# cbass_CBASS_FW_45000000h register map
Vendor: Texas Instruments
Registers are 32-bit, read-write, reset 0x0 unless marked. A register's access mark holds for its fields unless they carry their own. Offsets are as the file gives them; [hi:lo] are bit positions; {n}, {i} and the like mark numbered series; 'fields as' and 'values as' point back to an identical list.

## cbass_fw (part 2 of 2)
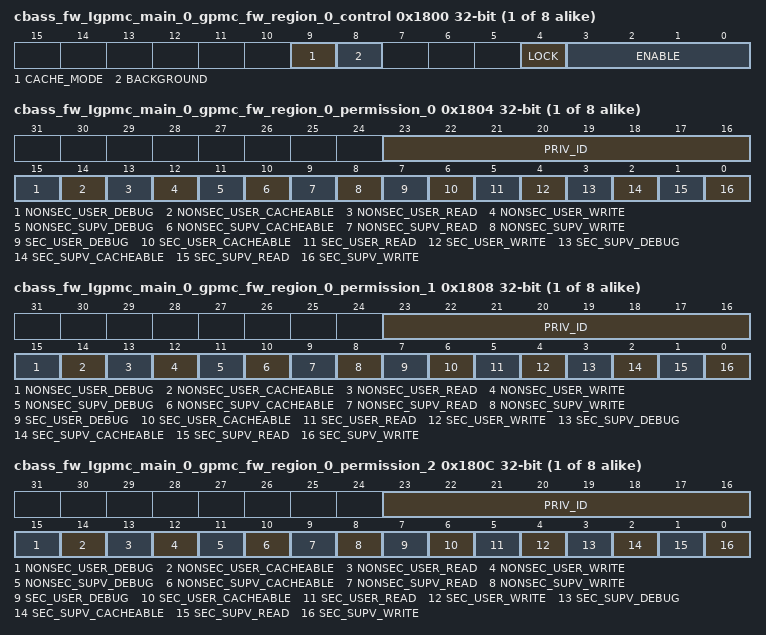
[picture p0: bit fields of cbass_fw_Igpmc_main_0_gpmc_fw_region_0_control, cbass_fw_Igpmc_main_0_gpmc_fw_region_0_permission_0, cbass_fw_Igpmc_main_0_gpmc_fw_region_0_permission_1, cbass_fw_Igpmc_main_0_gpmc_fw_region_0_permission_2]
{0x1800+0x20*i} cbass_fw_Igpmc_main_0_gpmc_fw_region_{i}_control access not given (i=0..7) — The FW Region {i} Control Register defines the control fields for the slave Igpmc_main_0.gpmc region {i} firewall.
  [9] CACHE_MODE rw — Cache mode for region. Set to 1 to check cache permissions. Set to 0 to ignore cache permissions. Reset Source: domain_default_rst_mod_g_rst_n
  [8] BACKGROUND rw — Background enable for region. There can be 1 backgroun region per FW and foreground regions can have overlapping addresses only with the background region. Reset Source: domain_default_rst_mod_g_rst_n
  [4] LOCK — Lock region. Once set region values cannot be modified. Reset Source: domain_default_rst_mod_g_rst_n (access R/W1TS)
  [3:0] ENABLE rw — Enable region. A value of 0xA enables, others disable. Reset Source: domain_default_rst_mod_g_rst_n
{0x1804+0x20*i} cbass_fw_Igpmc_main_0_gpmc_fw_region_{i}_permission_0 (i=0..7) — The FW Region {i} Permission 0 Register defines the permissions for the slave Igpmc_main_0.gpmc region {i} firewall.
  [23:16] PRIV_ID — Allowed privid. Reset Source: domain_default_rst_mod_g_rst_n
  [15] NONSEC_USER_DEBUG — Non-secure user debug allowed. Reset Source: domain_default_rst_mod_g_rst_n
  [14] NONSEC_USER_CACHEABLE — Non-secure user cacheable allowed. Reset Source: domain_default_rst_mod_g_rst_n
  [13] NONSEC_USER_READ — Non-secure user read allowed. Reset Source: domain_default_rst_mod_g_rst_n
  [12] NONSEC_USER_WRITE — Non-secure user write allowed. Reset Source: domain_default_rst_mod_g_rst_n
  [11] NONSEC_SUPV_DEBUG — Non-secure supervisor debug allowed. Reset Source: domain_default_rst_mod_g_rst_n
  [10] NONSEC_SUPV_CACHEABLE — Non-secure supervisor cacheable allowed. Reset Source: domain_default_rst_mod_g_rst_n
  [9] NONSEC_SUPV_READ — Non-secure supervisor read allowed. Reset Source: domain_default_rst_mod_g_rst_n
  [8] NONSEC_SUPV_WRITE — Non-secure supervisor write allowed. Reset Source: domain_default_rst_mod_g_rst_n
  [7] SEC_USER_DEBUG — Secure user debug allowed. Reset Source: domain_default_rst_mod_g_rst_n
  [6] SEC_USER_CACHEABLE — Secure user cacheable allowed. Reset Source: domain_default_rst_mod_g_rst_n
  [5] SEC_USER_READ — Secure user read allowed. Reset Source: domain_default_rst_mod_g_rst_n
  [4] SEC_USER_WRITE — Secure user write allowed. Reset Source: domain_default_rst_mod_g_rst_n
  [3] SEC_SUPV_DEBUG — Secure supervisor debug allowed. Reset Source: domain_default_rst_mod_g_rst_n
  [2] SEC_SUPV_CACHEABLE — Secure supervisor cacheable allowed. Reset Source: domain_default_rst_mod_g_rst_n
  [1] SEC_SUPV_READ — Secure supervisor read allowed. Reset Source: domain_default_rst_mod_g_rst_n
  [0] SEC_SUPV_WRITE — Secure supervisor write allowed. Reset Source: domain_default_rst_mod_g_rst_n
{0x1808+0x20*i} cbass_fw_Igpmc_main_0_gpmc_fw_region_{i}_permission_1 (i=0..7) — The FW Region {i} Permission 1 Register defines the permissions for the slave Igpmc_main_0.gpmc region {i} firewall.
  fields as cbass_fw_Igpmc_main_0_gpmc_fw_region_0_permission_0
{0x180C+0x20*i} cbass_fw_Igpmc_main_0_gpmc_fw_region_{i}_permission_2 (i=0..7) — The FW Region {i} Permission 2 Register defines the permissions for the slave Igpmc_main_0.gpmc region {i} firewall.
  fields as cbass_fw_Igpmc_main_0_gpmc_fw_region_0_permission_0
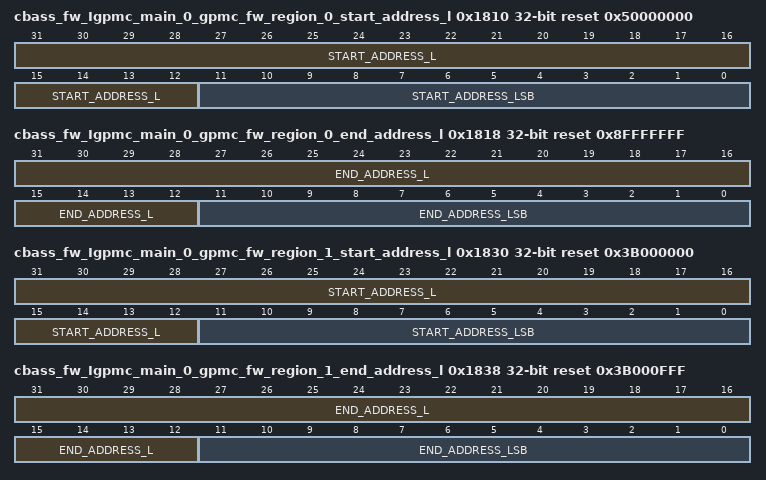
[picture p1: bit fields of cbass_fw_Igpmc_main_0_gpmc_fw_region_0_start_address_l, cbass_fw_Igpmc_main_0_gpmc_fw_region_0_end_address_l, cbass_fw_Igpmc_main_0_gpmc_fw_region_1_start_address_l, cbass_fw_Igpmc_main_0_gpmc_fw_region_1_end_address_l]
0x1810 cbass_fw_Igpmc_main_0_gpmc_fw_region_0_start_address_l access per field reset 0x50000000 — The FW Region 0 Start Address Low Register defines the start address bits 31 to 0 for the slave Igpmc_main_0.gpmc region 0 firewall.
  [31:12] START_ADDRESS_L rw — Start address bits 31 to 12. Lowest 12 bits are forced to 0 as address must be 4KB aligned. Reset Source: domain_default_rst_mod_g_rst_n
  [11:0] START_ADDRESS_LSB ro — Start address bits 11 to 0 are forced to 0 as address must be 4KB aligned. Reset Source: domain_default_rst_mod_g_rst_n
{0x1814+0x20*i} cbass_fw_Igpmc_main_0_gpmc_fw_region_{i}_start_address_h (i=0..7) — The FW Region {i} Start Address High Register defines the start address bits 47 to 32 for the slave Igpmc_main_0.gpmc region {i} firewall.
  [15:0] START_ADDRESS_H — Start address bits 47 to 32. Reset Source: domain_default_rst_mod_g_rst_n
0x1818 cbass_fw_Igpmc_main_0_gpmc_fw_region_0_end_address_l access per field reset 0x8FFFFFFF — The FW Region 0 End Address Low Register defines the end address bits 31 to 0 to include for the slave Igpmc_main_0.gpmc region 0 firewall.
  [31:12] END_ADDRESS_L rw — End address bits 31 to 12 to include in the match. Lowest 12 bits are forced to 1s as address must be 4KB aligned. Reset Source: domain_default_rst_mod_g_rst_n
  [11:0] END_ADDRESS_LSB ro — End address bits 11 to 0 are forced to 1s as address must be 4KB aligned minus 1. Reset Source: domain_default_rst_mod_g_rst_n
{0x181C+0x20*i} cbass_fw_Igpmc_main_0_gpmc_fw_region_{i}_end_address_h (i=0..7) — The FW Region {i} End Address High Register defines the end address bits 47 to 32 to include for the slave Igpmc_main_0.gpmc region {i} firewall.
  [15:0] END_ADDRESS_H — End address bits 47 to 32 to include in the match. Reset Source: domain_default_rst_mod_g_rst_n
0x1830 cbass_fw_Igpmc_main_0_gpmc_fw_region_1_start_address_l access per field reset 0x3B000000 — The FW Region 1 Start Address Low Register defines the start address bits 31 to 0 for the slave Igpmc_main_0.gpmc region 1 firewall.
  fields as cbass_fw_Igpmc_main_0_gpmc_fw_region_0_start_address_l
0x1838 cbass_fw_Igpmc_main_0_gpmc_fw_region_1_end_address_l access per field reset 0x3B000FFF — The FW Region 1 End Address Low Register defines the end address bits 31 to 0 to include for the slave Igpmc_main_0.gpmc region 1 firewall.
  fields as cbass_fw_Igpmc_main_0_gpmc_fw_region_0_end_address_l
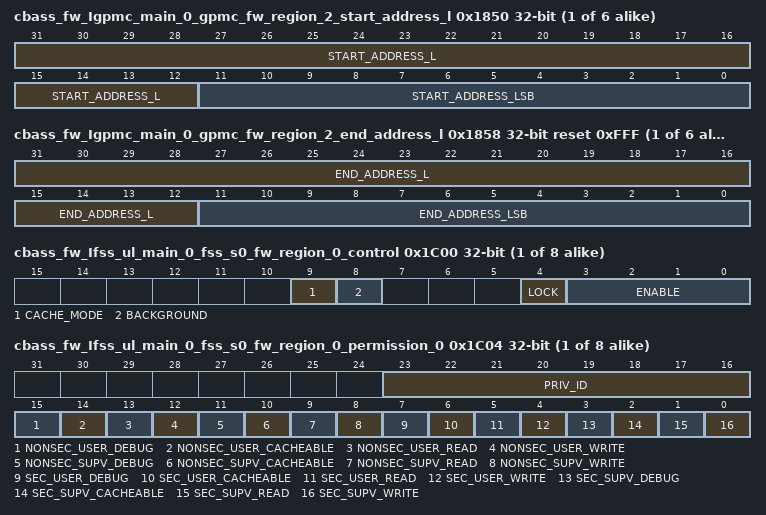
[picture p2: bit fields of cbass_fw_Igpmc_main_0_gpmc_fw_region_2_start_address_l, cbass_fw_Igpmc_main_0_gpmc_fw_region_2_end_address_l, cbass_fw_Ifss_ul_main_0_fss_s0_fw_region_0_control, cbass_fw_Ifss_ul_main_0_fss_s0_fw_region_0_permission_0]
{0x1810+0x20*i} cbass_fw_Igpmc_main_0_gpmc_fw_region_{i}_start_address_l access per field (i=2..7) — The FW Region {i} Start Address Low Register defines the start address bits 31 to 0 for the slave Igpmc_main_0.gpmc region {i} firewall.
  fields as cbass_fw_Igpmc_main_0_gpmc_fw_region_0_start_address_l
{0x1818+0x20*i} cbass_fw_Igpmc_main_0_gpmc_fw_region_{i}_end_address_l access per field reset 0xFFF (i=2..7) — The FW Region {i} End Address Low Register defines the end address bits 31 to 0 to include for the slave Igpmc_main_0.gpmc region {i} firewall.
  fields as cbass_fw_Igpmc_main_0_gpmc_fw_region_0_end_address_l
{0x1C00+0x20*i} cbass_fw_Ifss_ul_main_0_fss_s0_fw_region_{i}_control access not given (i=0..7) — The FW Region {i} Control Register defines the control fields for the slave Ifss_ul_main_0.fss_s0 region {i} firewall.
  fields as cbass_fw_Igpmc_main_0_gpmc_fw_region_0_control
{0x1C04+0x20*i} cbass_fw_Ifss_ul_main_0_fss_s0_fw_region_{i}_permission_0 (i=0..7) — The FW Region {i} Permission 0 Register defines the permissions for the slave Ifss_ul_main_0.fss_s0 region {i} firewall.
  fields as cbass_fw_Igpmc_main_0_gpmc_fw_region_0_permission_0
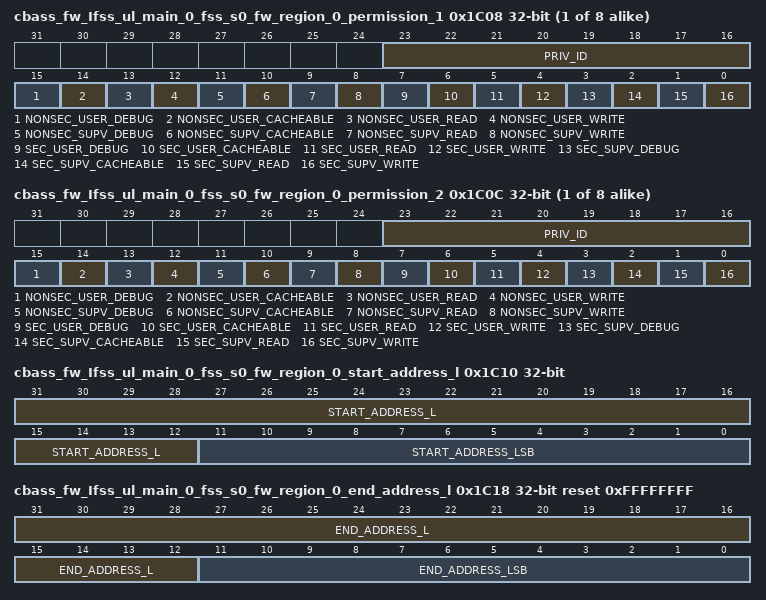
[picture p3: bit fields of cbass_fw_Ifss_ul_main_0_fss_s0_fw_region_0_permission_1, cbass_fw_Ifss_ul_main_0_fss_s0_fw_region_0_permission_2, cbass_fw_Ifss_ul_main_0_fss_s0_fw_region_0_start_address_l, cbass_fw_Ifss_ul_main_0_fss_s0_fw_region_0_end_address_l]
{0x1C08+0x20*i} cbass_fw_Ifss_ul_main_0_fss_s0_fw_region_{i}_permission_1 (i=0..7) — The FW Region {i} Permission 1 Register defines the permissions for the slave Ifss_ul_main_0.fss_s0 region {i} firewall.
  fields as cbass_fw_Igpmc_main_0_gpmc_fw_region_0_permission_0
{0x1C0C+0x20*i} cbass_fw_Ifss_ul_main_0_fss_s0_fw_region_{i}_permission_2 (i=0..7) — The FW Region {i} Permission 2 Register defines the permissions for the slave Ifss_ul_main_0.fss_s0 region {i} firewall.
  fields as cbass_fw_Igpmc_main_0_gpmc_fw_region_0_permission_0
0x1C10 cbass_fw_Ifss_ul_main_0_fss_s0_fw_region_0_start_address_l access per field — The FW Region 0 Start Address Low Register defines the start address bits 31 to 0 for the slave Ifss_ul_main_0.fss_s0 region 0 firewall.
  fields as cbass_fw_Igpmc_main_0_gpmc_fw_region_0_start_address_l
0x1C14 cbass_fw_Ifss_ul_main_0_fss_s0_fw_region_0_start_address_h reset 0x4 — The FW Region 0 Start Address High Register defines the start address bits 47 to 32 for the slave Ifss_ul_main_0.fss_s0 region 0 firewall.
  fields as cbass_fw_Igpmc_main_0_gpmc_fw_region_0_start_address_h
0x1C18 cbass_fw_Ifss_ul_main_0_fss_s0_fw_region_0_end_address_l access per field reset 0xFFFFFFFF — The FW Region 0 End Address Low Register defines the end address bits 31 to 0 to include for the slave Ifss_ul_main_0.fss_s0 region 0 firewall.
  fields as cbass_fw_Igpmc_main_0_gpmc_fw_region_0_end_address_l
0x1C1C cbass_fw_Ifss_ul_main_0_fss_s0_fw_region_0_end_address_h reset 0x4 — The FW Region 0 End Address High Register defines the end address bits 47 to 32 to include for the slave Ifss_ul_main_0.fss_s0 region 0 firewall.
  fields as cbass_fw_Igpmc_main_0_gpmc_fw_region_0_end_address_h
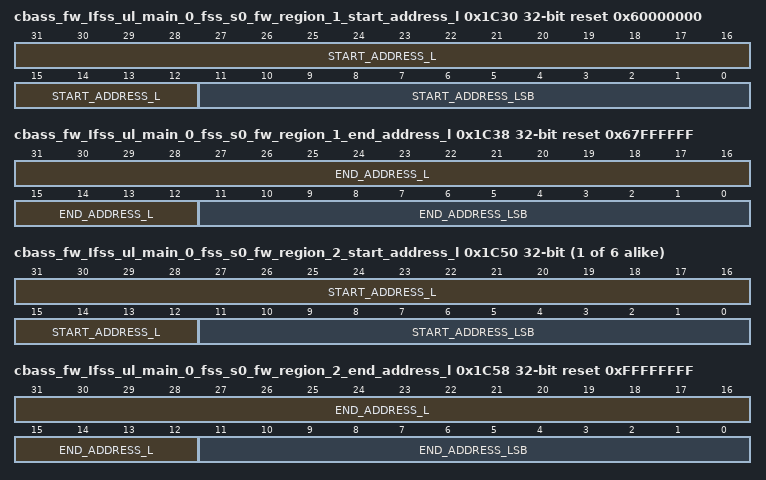
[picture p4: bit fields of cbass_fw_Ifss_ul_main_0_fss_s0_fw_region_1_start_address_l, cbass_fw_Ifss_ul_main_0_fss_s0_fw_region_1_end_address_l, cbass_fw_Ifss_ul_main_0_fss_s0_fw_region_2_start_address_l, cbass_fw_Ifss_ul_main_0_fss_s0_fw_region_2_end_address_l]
0x1C30 cbass_fw_Ifss_ul_main_0_fss_s0_fw_region_1_start_address_l access per field reset 0x60000000 — The FW Region 1 Start Address Low Register defines the start address bits 31 to 0 for the slave Ifss_ul_main_0.fss_s0 region 1 firewall.
  fields as cbass_fw_Igpmc_main_0_gpmc_fw_region_0_start_address_l
0x1C34 cbass_fw_Ifss_ul_main_0_fss_s0_fw_region_1_start_address_h — The FW Region 1 Start Address High Register defines the start address bits 47 to 32 for the slave Ifss_ul_main_0.fss_s0 region 1 firewall.
  fields as cbass_fw_Igpmc_main_0_gpmc_fw_region_0_start_address_h
0x1C38 cbass_fw_Ifss_ul_main_0_fss_s0_fw_region_1_end_address_l access per field reset 0x67FFFFFF — The FW Region 1 End Address Low Register defines the end address bits 31 to 0 to include for the slave Ifss_ul_main_0.fss_s0 region 1 firewall.
  fields as cbass_fw_Igpmc_main_0_gpmc_fw_region_0_end_address_l
0x1C3C cbass_fw_Ifss_ul_main_0_fss_s0_fw_region_1_end_address_h — The FW Region 1 End Address High Register defines the end address bits 47 to 32 to include for the slave Ifss_ul_main_0.fss_s0 region 1 firewall.
  fields as cbass_fw_Igpmc_main_0_gpmc_fw_region_0_end_address_h
{0x1C10+0x20*i} cbass_fw_Ifss_ul_main_0_fss_s0_fw_region_{i}_start_address_l access per field (i=2..7) — The FW Region {i} Start Address Low Register defines the start address bits 31 to 0 for the slave Ifss_ul_main_0.fss_s0 region {i} firewall.
  fields as cbass_fw_Igpmc_main_0_gpmc_fw_region_0_start_address_l
0x1C54 cbass_fw_Ifss_ul_main_0_fss_s0_fw_region_2_start_address_h reset 0x5 — The FW Region 2 Start Address High Register defines the start address bits 47 to 32 for the slave Ifss_ul_main_0.fss_s0 region 2 firewall.
  fields as cbass_fw_Igpmc_main_0_gpmc_fw_region_0_start_address_h
0x1C58 cbass_fw_Ifss_ul_main_0_fss_s0_fw_region_2_end_address_l access per field reset 0xFFFFFFFF — The FW Region 2 End Address Low Register defines the end address bits 31 to 0 to include for the slave Ifss_ul_main_0.fss_s0 region 2 firewall.
  fields as cbass_fw_Igpmc_main_0_gpmc_fw_region_0_end_address_l
0x1C5C cbass_fw_Ifss_ul_main_0_fss_s0_fw_region_2_end_address_h reset 0x5 — The FW Region 2 End Address High Register defines the end address bits 47 to 32 to include for the slave Ifss_ul_main_0.fss_s0 region 2 firewall.
  fields as cbass_fw_Igpmc_main_0_gpmc_fw_region_0_end_address_h
{0x1C14+0x20*i} cbass_fw_Ifss_ul_main_0_fss_s0_fw_region_{i}_start_address_h (i=3..7) — The FW Region {i} Start Address High Register defines the start address bits 47 to 32 for the slave Ifss_ul_main_0.fss_s0 region {i} firewall.
  fields as cbass_fw_Igpmc_main_0_gpmc_fw_region_0_start_address_h
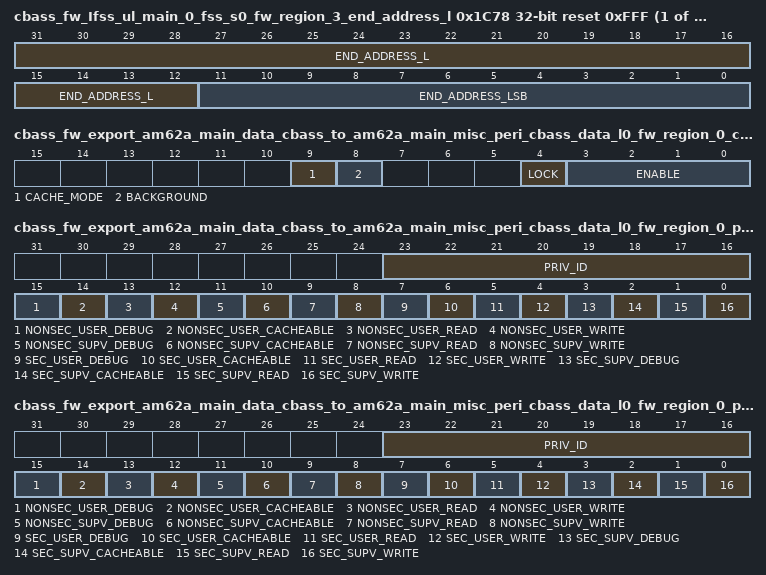
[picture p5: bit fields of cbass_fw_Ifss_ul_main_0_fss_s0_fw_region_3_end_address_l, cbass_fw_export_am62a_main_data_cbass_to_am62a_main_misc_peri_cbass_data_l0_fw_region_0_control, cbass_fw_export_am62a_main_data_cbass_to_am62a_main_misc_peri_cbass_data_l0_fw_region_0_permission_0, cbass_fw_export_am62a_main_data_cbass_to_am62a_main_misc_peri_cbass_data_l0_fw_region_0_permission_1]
{0x1C18+0x20*i} cbass_fw_Ifss_ul_main_0_fss_s0_fw_region_{i}_end_address_l access per field reset 0xFFF (i=3..7) — The FW Region {i} End Address Low Register defines the end address bits 31 to 0 to include for the slave Ifss_ul_main_0.fss_s0 region {i} firewall.
  fields as cbass_fw_Igpmc_main_0_gpmc_fw_region_0_end_address_l
{0x1C1C+0x20*i} cbass_fw_Ifss_ul_main_0_fss_s0_fw_region_{i}_end_address_h (i=3..7) — The FW Region {i} End Address High Register defines the end address bits 47 to 32 to include for the slave Ifss_ul_main_0.fss_s0 region {i} firewall.
  fields as cbass_fw_Igpmc_main_0_gpmc_fw_region_0_end_address_h
{0x2000+0x20*i} cbass_fw_export_am62a_main_data_cbass_to_am62a_main_misc_peri_cbass_data_l0_fw_region_{i}_control access not given (i=0..15) — The FW Region {i} Control Register defines the control fields for the slave export_am62a_main_data_cbass_to_am62a_main_misc_peri_cbass_data_l0.slv region {i} firewall.
  fields as cbass_fw_Igpmc_main_0_gpmc_fw_region_0_control
{0x2004+0x20*i} cbass_fw_export_am62a_main_data_cbass_to_am62a_main_misc_peri_cbass_data_l0_fw_region_{i}_permission_0 (i=0..15) — The FW Region {i} Permission 0 Register defines the permissions for the slave export_am62a_main_data_cbass_to_am62a_main_misc_peri_cbass_data_l0.slv region {i} firewall.
  fields as cbass_fw_Igpmc_main_0_gpmc_fw_region_0_permission_0
{0x2008+0x20*i} cbass_fw_export_am62a_main_data_cbass_to_am62a_main_misc_peri_cbass_data_l0_fw_region_{i}_permission_1 (i=0..15) — The FW Region {i} Permission 1 Register defines the permissions for the slave export_am62a_main_data_cbass_to_am62a_main_misc_peri_cbass_data_l0.slv region {i} firewall.
  fields as cbass_fw_Igpmc_main_0_gpmc_fw_region_0_permission_0
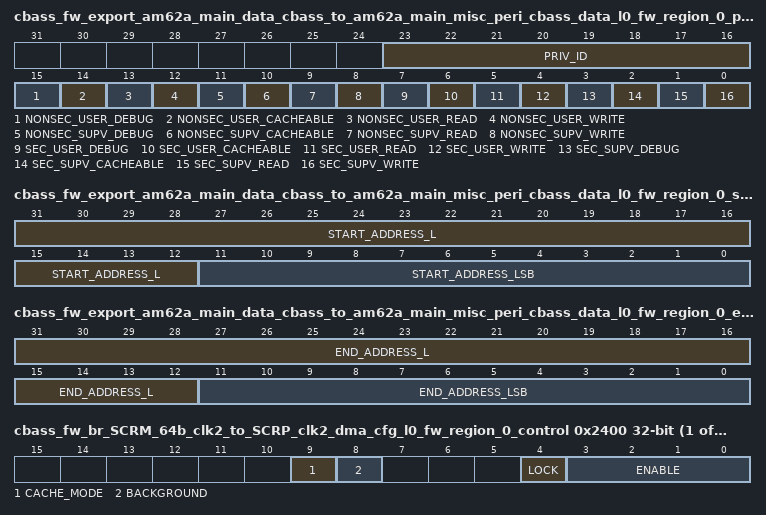
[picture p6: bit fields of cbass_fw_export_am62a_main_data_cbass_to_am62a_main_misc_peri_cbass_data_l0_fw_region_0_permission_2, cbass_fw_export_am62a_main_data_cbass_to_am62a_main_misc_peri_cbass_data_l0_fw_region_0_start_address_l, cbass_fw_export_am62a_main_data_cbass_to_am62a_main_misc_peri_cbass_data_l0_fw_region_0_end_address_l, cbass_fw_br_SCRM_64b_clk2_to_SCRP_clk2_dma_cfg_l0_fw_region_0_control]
{0x200C+0x20*i} cbass_fw_export_am62a_main_data_cbass_to_am62a_main_misc_peri_cbass_data_l0_fw_region_{i}_permission_2 (i=0..15) — The FW Region {i} Permission 2 Register defines the permissions for the slave export_am62a_main_data_cbass_to_am62a_main_misc_peri_cbass_data_l0.slv region {i} firewall.
  fields as cbass_fw_Igpmc_main_0_gpmc_fw_region_0_permission_0
{0x2010+0x20*i} cbass_fw_export_am62a_main_data_cbass_to_am62a_main_misc_peri_cbass_data_l0_fw_region_{i}_start_address_l access per field (i=0..15) — The FW Region {i} Start Address Low Register defines the start address bits 31 to 0 for the slave export_am62a_main_data_cbass_to_am62a_main_misc_peri_cbass_data_l0.slv region {i} firewall.
  fields as cbass_fw_Igpmc_main_0_gpmc_fw_region_0_start_address_l
{0x2014+0x20*i} cbass_fw_export_am62a_main_data_cbass_to_am62a_main_misc_peri_cbass_data_l0_fw_region_{i}_start_address_h (i=0..15) — The FW Region {i} Start Address High Register defines the start address bits 47 to 32 for the slave export_am62a_main_data_cbass_to_am62a_main_misc_peri_cbass_data_l0.slv region {i} firewall.
  fields as cbass_fw_Igpmc_main_0_gpmc_fw_region_0_start_address_h
{0x2018+0x20*i} cbass_fw_export_am62a_main_data_cbass_to_am62a_main_misc_peri_cbass_data_l0_fw_region_{i}_end_address_l access per field reset 0xFFF (i=0..15) — The FW Region {i} End Address Low Register defines the end address bits 31 to 0 to include for the slave export_am62a_main_data_cbass_to_am62a_main_misc_peri_cbass_data_l0.slv region {i} firewall.
  fields as cbass_fw_Igpmc_main_0_gpmc_fw_region_0_end_address_l
{0x201C+0x20*i} cbass_fw_export_am62a_main_data_cbass_to_am62a_main_misc_peri_cbass_data_l0_fw_region_{i}_end_address_h (i=0..15) — The FW Region {i} End Address High Register defines the end address bits 47 to 32 to include for the slave export_am62a_main_data_cbass_to_am62a_main_misc_peri_cbass_data_l0.slv region {i} firewall.
  fields as cbass_fw_Igpmc_main_0_gpmc_fw_region_0_end_address_h
{0x2400+0x20*i} cbass_fw_br_SCRM_64b_clk2_to_SCRP_clk2_dma_cfg_l0_fw_region_{i}_control access not given (i=0..31) — The FW Region {i} Control Register defines the control fields for the slave br_SCRM_64b_clk2_to_SCRP_clk2_dma_cfg_l0 region {i} firewall.
  fields as cbass_fw_Igpmc_main_0_gpmc_fw_region_0_control
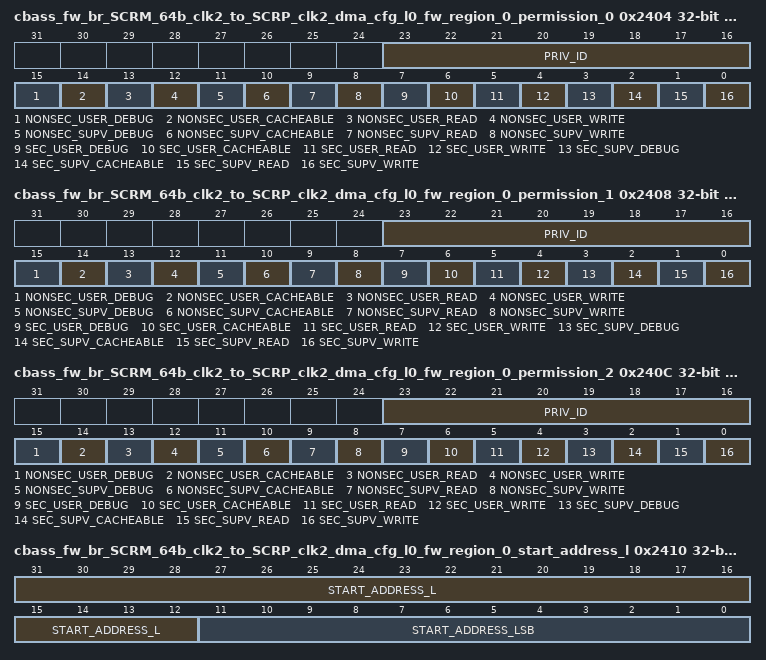
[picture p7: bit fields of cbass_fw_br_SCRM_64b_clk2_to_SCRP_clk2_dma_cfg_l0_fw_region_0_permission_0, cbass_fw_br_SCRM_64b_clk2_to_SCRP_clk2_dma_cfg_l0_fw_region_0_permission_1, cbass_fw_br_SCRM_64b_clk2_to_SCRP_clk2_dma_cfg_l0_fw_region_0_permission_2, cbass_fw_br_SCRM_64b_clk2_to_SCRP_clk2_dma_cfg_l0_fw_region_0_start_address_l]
{0x2404+0x20*i} cbass_fw_br_SCRM_64b_clk2_to_SCRP_clk2_dma_cfg_l0_fw_region_{i}_permission_0 (i=0..31) — The FW Region {i} Permission 0 Register defines the permissions for the slave br_SCRM_64b_clk2_to_SCRP_clk2_dma_cfg_l0 region {i} firewall.
  fields as cbass_fw_Igpmc_main_0_gpmc_fw_region_0_permission_0
{0x2408+0x20*i} cbass_fw_br_SCRM_64b_clk2_to_SCRP_clk2_dma_cfg_l0_fw_region_{i}_permission_1 (i=0..31) — The FW Region {i} Permission 1 Register defines the permissions for the slave br_SCRM_64b_clk2_to_SCRP_clk2_dma_cfg_l0 region {i} firewall.
  fields as cbass_fw_Igpmc_main_0_gpmc_fw_region_0_permission_0
{0x240C+0x20*i} cbass_fw_br_SCRM_64b_clk2_to_SCRP_clk2_dma_cfg_l0_fw_region_{i}_permission_2 (i=0..31) — The FW Region {i} Permission 2 Register defines the permissions for the slave br_SCRM_64b_clk2_to_SCRP_clk2_dma_cfg_l0 region {i} firewall.
  fields as cbass_fw_Igpmc_main_0_gpmc_fw_region_0_permission_0
{0x2410+0x20*i} cbass_fw_br_SCRM_64b_clk2_to_SCRP_clk2_dma_cfg_l0_fw_region_{i}_start_address_l access per field (i=0..31) — The FW Region {i} Start Address Low Register defines the start address bits 31 to 0 for the slave br_SCRM_64b_clk2_to_SCRP_clk2_dma_cfg_l0 region {i} firewall.
  fields as cbass_fw_Igpmc_main_0_gpmc_fw_region_0_start_address_l
{0x2414+0x20*i} cbass_fw_br_SCRM_64b_clk2_to_SCRP_clk2_dma_cfg_l0_fw_region_{i}_start_address_h (i=0..31) — The FW Region {i} Start Address High Register defines the start address bits 47 to 32 for the slave br_SCRM_64b_clk2_to_SCRP_clk2_dma_cfg_l0 region {i} firewall.
  fields as cbass_fw_Igpmc_main_0_gpmc_fw_region_0_start_address_h
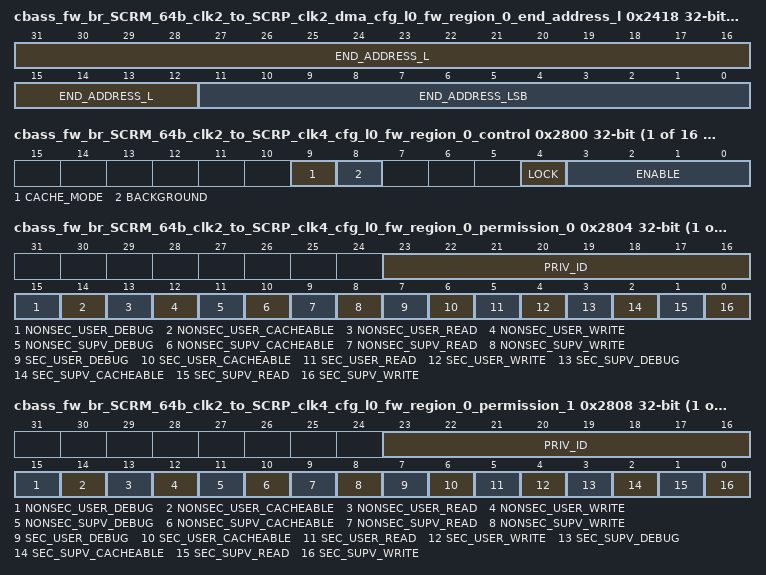
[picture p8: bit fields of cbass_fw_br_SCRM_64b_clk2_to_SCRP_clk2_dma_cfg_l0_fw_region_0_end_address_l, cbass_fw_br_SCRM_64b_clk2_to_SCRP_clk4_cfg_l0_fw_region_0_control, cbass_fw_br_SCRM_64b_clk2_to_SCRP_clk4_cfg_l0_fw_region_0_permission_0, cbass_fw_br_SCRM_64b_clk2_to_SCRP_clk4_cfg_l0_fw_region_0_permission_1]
{0x2418+0x20*i} cbass_fw_br_SCRM_64b_clk2_to_SCRP_clk2_dma_cfg_l0_fw_region_{i}_end_address_l access per field reset 0xFFF (i=0..31) — The FW Region {i} End Address Low Register defines the end address bits 31 to 0 to include for the slave br_SCRM_64b_clk2_to_SCRP_clk2_dma_cfg_l0 region {i} firewall.
  fields as cbass_fw_Igpmc_main_0_gpmc_fw_region_0_end_address_l
{0x241C+0x20*i} cbass_fw_br_SCRM_64b_clk2_to_SCRP_clk2_dma_cfg_l0_fw_region_{i}_end_address_h (i=0..31) — The FW Region {i} End Address High Register defines the end address bits 47 to 32 to include for the slave br_SCRM_64b_clk2_to_SCRP_clk2_dma_cfg_l0 region {i} firewall.
  fields as cbass_fw_Igpmc_main_0_gpmc_fw_region_0_end_address_h
{0x2800+0x20*i} cbass_fw_br_SCRM_64b_clk2_to_SCRP_clk4_cfg_l0_fw_region_{i}_control access not given (i=0..15) — The FW Region {i} Control Register defines the control fields for the slave br_SCRM_64b_clk2_to_SCRP_clk4_cfg_l0 region {i} firewall.
  fields as cbass_fw_Igpmc_main_0_gpmc_fw_region_0_control
{0x2804+0x20*i} cbass_fw_br_SCRM_64b_clk2_to_SCRP_clk4_cfg_l0_fw_region_{i}_permission_0 (i=0..15) — The FW Region {i} Permission 0 Register defines the permissions for the slave br_SCRM_64b_clk2_to_SCRP_clk4_cfg_l0 region {i} firewall.
  fields as cbass_fw_Igpmc_main_0_gpmc_fw_region_0_permission_0
{0x2808+0x20*i} cbass_fw_br_SCRM_64b_clk2_to_SCRP_clk4_cfg_l0_fw_region_{i}_permission_1 (i=0..15) — The FW Region {i} Permission 1 Register defines the permissions for the slave br_SCRM_64b_clk2_to_SCRP_clk4_cfg_l0 region {i} firewall.
  fields as cbass_fw_Igpmc_main_0_gpmc_fw_region_0_permission_0
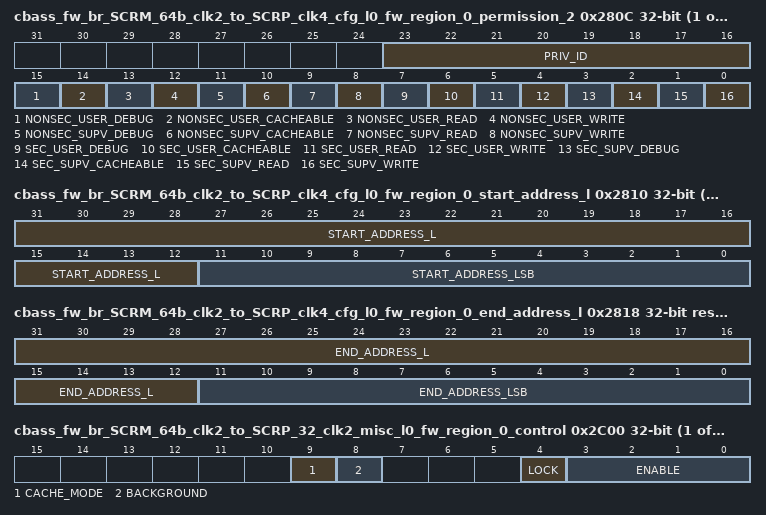
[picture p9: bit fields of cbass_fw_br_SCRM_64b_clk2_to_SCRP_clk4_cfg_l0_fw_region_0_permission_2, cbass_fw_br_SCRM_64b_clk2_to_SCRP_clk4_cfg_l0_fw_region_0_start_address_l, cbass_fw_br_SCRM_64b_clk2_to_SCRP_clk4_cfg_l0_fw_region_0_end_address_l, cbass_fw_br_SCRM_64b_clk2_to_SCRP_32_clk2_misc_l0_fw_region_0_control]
{0x280C+0x20*i} cbass_fw_br_SCRM_64b_clk2_to_SCRP_clk4_cfg_l0_fw_region_{i}_permission_2 (i=0..15) — The FW Region {i} Permission 2 Register defines the permissions for the slave br_SCRM_64b_clk2_to_SCRP_clk4_cfg_l0 region {i} firewall.
  fields as cbass_fw_Igpmc_main_0_gpmc_fw_region_0_permission_0
{0x2810+0x20*i} cbass_fw_br_SCRM_64b_clk2_to_SCRP_clk4_cfg_l0_fw_region_{i}_start_address_l access per field (i=0..15) — The FW Region {i} Start Address Low Register defines the start address bits 31 to 0 for the slave br_SCRM_64b_clk2_to_SCRP_clk4_cfg_l0 region {i} firewall.
  fields as cbass_fw_Igpmc_main_0_gpmc_fw_region_0_start_address_l
{0x2814+0x20*i} cbass_fw_br_SCRM_64b_clk2_to_SCRP_clk4_cfg_l0_fw_region_{i}_start_address_h (i=0..15) — The FW Region {i} Start Address High Register defines the start address bits 47 to 32 for the slave br_SCRM_64b_clk2_to_SCRP_clk4_cfg_l0 region {i} firewall.
  fields as cbass_fw_Igpmc_main_0_gpmc_fw_region_0_start_address_h
{0x2818+0x20*i} cbass_fw_br_SCRM_64b_clk2_to_SCRP_clk4_cfg_l0_fw_region_{i}_end_address_l access per field reset 0xFFF (i=0..15) — The FW Region {i} End Address Low Register defines the end address bits 31 to 0 to include for the slave br_SCRM_64b_clk2_to_SCRP_clk4_cfg_l0 region {i} firewall.
  fields as cbass_fw_Igpmc_main_0_gpmc_fw_region_0_end_address_l
{0x281C+0x20*i} cbass_fw_br_SCRM_64b_clk2_to_SCRP_clk4_cfg_l0_fw_region_{i}_end_address_h (i=0..15) — The FW Region {i} End Address High Register defines the end address bits 47 to 32 to include for the slave br_SCRM_64b_clk2_to_SCRP_clk4_cfg_l0 region {i} firewall.
  fields as cbass_fw_Igpmc_main_0_gpmc_fw_region_0_end_address_h
{0x2C00+0x20*i} cbass_fw_br_SCRM_64b_clk2_to_SCRP_32_clk2_misc_l0_fw_region_{i}_control access not given (i=0..15) — The FW Region {i} Control Register defines the control fields for the slave br_SCRM_64b_clk2_to_SCRP_32_clk2_misc_l0 region {i} firewall.
  fields as cbass_fw_Igpmc_main_0_gpmc_fw_region_0_control
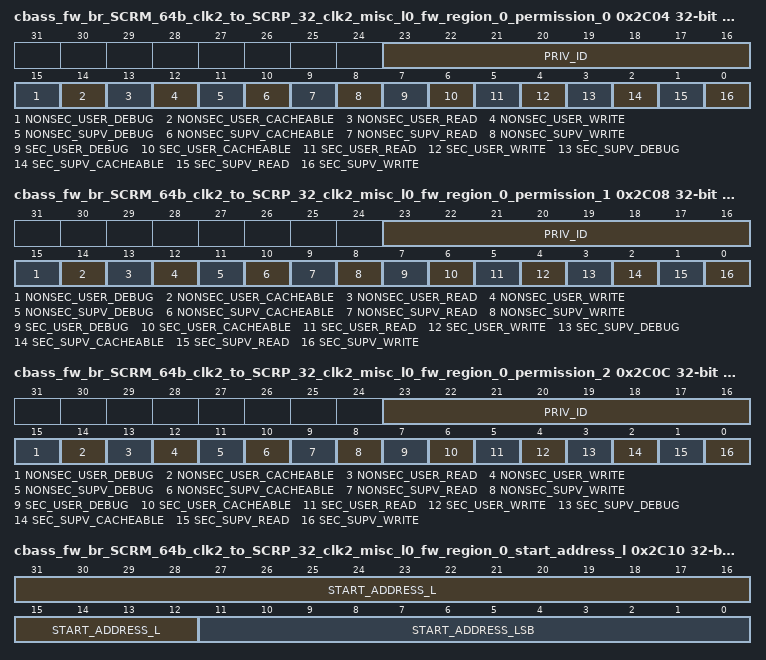
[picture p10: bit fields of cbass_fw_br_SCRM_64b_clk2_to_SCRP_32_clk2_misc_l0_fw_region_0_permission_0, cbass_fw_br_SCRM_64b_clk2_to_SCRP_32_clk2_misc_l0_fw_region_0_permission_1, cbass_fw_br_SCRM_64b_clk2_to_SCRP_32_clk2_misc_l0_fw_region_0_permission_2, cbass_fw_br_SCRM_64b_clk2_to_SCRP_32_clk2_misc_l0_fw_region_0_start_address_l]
{0x2C04+0x20*i} cbass_fw_br_SCRM_64b_clk2_to_SCRP_32_clk2_misc_l0_fw_region_{i}_permission_0 (i=0..15) — The FW Region {i} Permission 0 Register defines the permissions for the slave br_SCRM_64b_clk2_to_SCRP_32_clk2_misc_l0 region {i} firewall.
  fields as cbass_fw_Igpmc_main_0_gpmc_fw_region_0_permission_0
{0x2C08+0x20*i} cbass_fw_br_SCRM_64b_clk2_to_SCRP_32_clk2_misc_l0_fw_region_{i}_permission_1 (i=0..15) — The FW Region {i} Permission 1 Register defines the permissions for the slave br_SCRM_64b_clk2_to_SCRP_32_clk2_misc_l0 region {i} firewall.
  fields as cbass_fw_Igpmc_main_0_gpmc_fw_region_0_permission_0
{0x2C0C+0x20*i} cbass_fw_br_SCRM_64b_clk2_to_SCRP_32_clk2_misc_l0_fw_region_{i}_permission_2 (i=0..15) — The FW Region {i} Permission 2 Register defines the permissions for the slave br_SCRM_64b_clk2_to_SCRP_32_clk2_misc_l0 region {i} firewall.
  fields as cbass_fw_Igpmc_main_0_gpmc_fw_region_0_permission_0
{0x2C10+0x20*i} cbass_fw_br_SCRM_64b_clk2_to_SCRP_32_clk2_misc_l0_fw_region_{i}_start_address_l access per field (i=0..15) — The FW Region {i} Start Address Low Register defines the start address bits 31 to 0 for the slave br_SCRM_64b_clk2_to_SCRP_32_clk2_misc_l0 region {i} firewall.
  fields as cbass_fw_Igpmc_main_0_gpmc_fw_region_0_start_address_l
{0x2C14+0x20*i} cbass_fw_br_SCRM_64b_clk2_to_SCRP_32_clk2_misc_l0_fw_region_{i}_start_address_h (i=0..15) — The FW Region {i} Start Address High Register defines the start address bits 47 to 32 for the slave br_SCRM_64b_clk2_to_SCRP_32_clk2_misc_l0 region {i} firewall.
  fields as cbass_fw_Igpmc_main_0_gpmc_fw_region_0_start_address_h
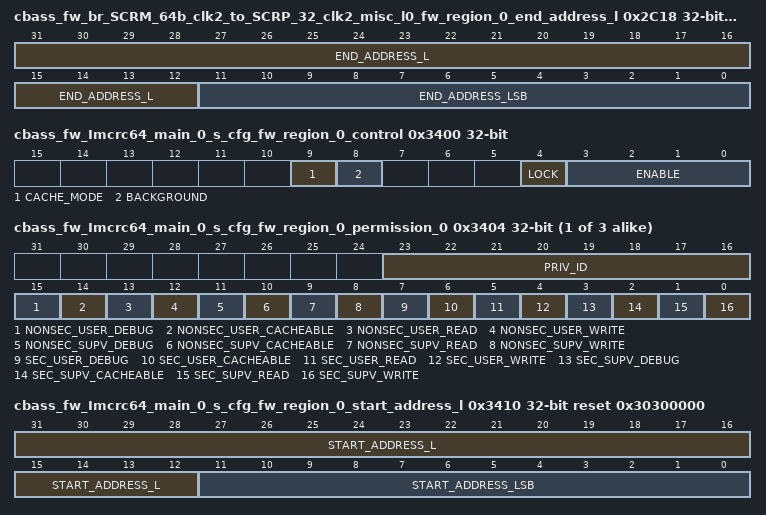
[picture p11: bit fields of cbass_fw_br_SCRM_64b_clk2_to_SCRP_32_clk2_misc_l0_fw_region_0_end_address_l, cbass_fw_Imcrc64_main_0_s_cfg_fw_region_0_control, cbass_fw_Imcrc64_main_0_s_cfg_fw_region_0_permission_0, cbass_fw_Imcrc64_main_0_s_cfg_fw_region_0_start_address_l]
{0x2C18+0x20*i} cbass_fw_br_SCRM_64b_clk2_to_SCRP_32_clk2_misc_l0_fw_region_{i}_end_address_l access per field reset 0xFFF (i=0..15) — The FW Region {i} End Address Low Register defines the end address bits 31 to 0 to include for the slave br_SCRM_64b_clk2_to_SCRP_32_clk2_misc_l0 region {i} firewall.
  fields as cbass_fw_Igpmc_main_0_gpmc_fw_region_0_end_address_l
{0x2C1C+0x20*i} cbass_fw_br_SCRM_64b_clk2_to_SCRP_32_clk2_misc_l0_fw_region_{i}_end_address_h (i=0..15) — The FW Region {i} End Address High Register defines the end address bits 47 to 32 to include for the slave br_SCRM_64b_clk2_to_SCRP_32_clk2_misc_l0 region {i} firewall.
  fields as cbass_fw_Igpmc_main_0_gpmc_fw_region_0_end_address_h
0x3400 cbass_fw_Imcrc64_main_0_s_cfg_fw_region_0_control access not given — The FW Region 0 Control Register defines the control fields for the slave Imcrc64_main_0.s_cfg region 0 firewall.
  fields as cbass_fw_Igpmc_main_0_gpmc_fw_region_0_control
{0x3404+4i} cbass_fw_Imcrc64_main_0_s_cfg_fw_region_0_permission_{i} (i=0..2) — The FW Region 0 Permission {i} Register defines the permissions for the slave Imcrc64_main_0.s_cfg region 0 firewall.
  fields as cbass_fw_Igpmc_main_0_gpmc_fw_region_0_permission_0
0x3410 cbass_fw_Imcrc64_main_0_s_cfg_fw_region_0_start_address_l access per field reset 0x30300000 — The FW Region 0 Start Address Low Register defines the start address bits 31 to 0 for the slave Imcrc64_main_0.s_cfg region 0 firewall.
  fields as cbass_fw_Igpmc_main_0_gpmc_fw_region_0_start_address_l
0x3414 cbass_fw_Imcrc64_main_0_s_cfg_fw_region_0_start_address_h — The FW Region 0 Start Address High Register defines the start address bits 47 to 32 for the slave Imcrc64_main_0.s_cfg region 0 firewall.
  fields as cbass_fw_Igpmc_main_0_gpmc_fw_region_0_start_address_h
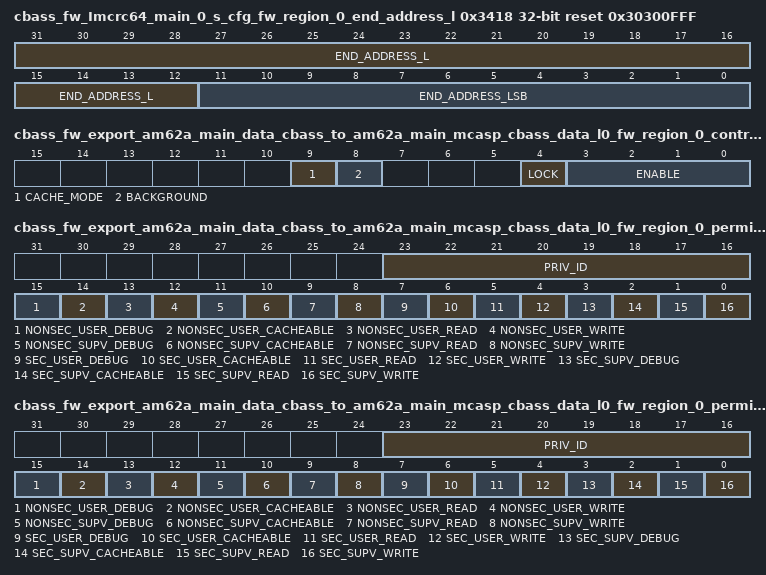
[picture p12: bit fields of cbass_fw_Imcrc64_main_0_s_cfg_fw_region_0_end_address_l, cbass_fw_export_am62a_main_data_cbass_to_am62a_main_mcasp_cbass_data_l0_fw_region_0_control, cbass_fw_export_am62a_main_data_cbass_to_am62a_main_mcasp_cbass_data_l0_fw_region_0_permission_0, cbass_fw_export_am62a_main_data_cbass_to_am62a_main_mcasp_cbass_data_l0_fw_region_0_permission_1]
0x3418 cbass_fw_Imcrc64_main_0_s_cfg_fw_region_0_end_address_l access per field reset 0x30300FFF — The FW Region 0 End Address Low Register defines the end address bits 31 to 0 to include for the slave Imcrc64_main_0.s_cfg region 0 firewall.
  fields as cbass_fw_Igpmc_main_0_gpmc_fw_region_0_end_address_l
0x341C cbass_fw_Imcrc64_main_0_s_cfg_fw_region_0_end_address_h — The FW Region 0 End Address High Register defines the end address bits 47 to 32 to include for the slave Imcrc64_main_0.s_cfg region 0 firewall.
  fields as cbass_fw_Igpmc_main_0_gpmc_fw_region_0_end_address_h
{0x3800+0x20*i} cbass_fw_export_am62a_main_data_cbass_to_am62a_main_mcasp_cbass_data_l0_fw_region_{i}_control access not given (i=0..7) — The FW Region {i} Control Register defines the control fields for the slave export_am62a_main_data_cbass_to_am62a_main_mcasp_cbass_data_l0.slv region {i} firewall.
  fields as cbass_fw_Igpmc_main_0_gpmc_fw_region_0_control
{0x3804+0x20*i} cbass_fw_export_am62a_main_data_cbass_to_am62a_main_mcasp_cbass_data_l0_fw_region_{i}_permission_0 (i=0..7) — The FW Region {i} Permission 0 Register defines the permissions for the slave export_am62a_main_data_cbass_to_am62a_main_mcasp_cbass_data_l0.slv region {i} firewall.
  fields as cbass_fw_Igpmc_main_0_gpmc_fw_region_0_permission_0
{0x3808+0x20*i} cbass_fw_export_am62a_main_data_cbass_to_am62a_main_mcasp_cbass_data_l0_fw_region_{i}_permission_1 (i=0..7) — The FW Region {i} Permission 1 Register defines the permissions for the slave export_am62a_main_data_cbass_to_am62a_main_mcasp_cbass_data_l0.slv region {i} firewall.
  fields as cbass_fw_Igpmc_main_0_gpmc_fw_region_0_permission_0
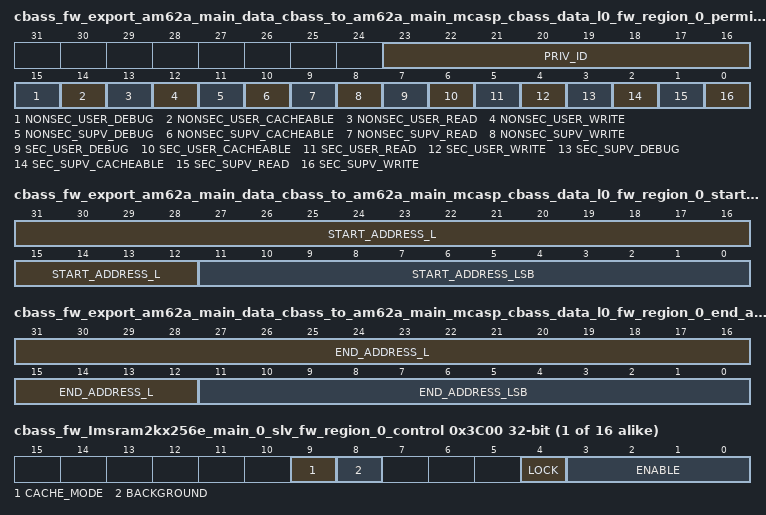
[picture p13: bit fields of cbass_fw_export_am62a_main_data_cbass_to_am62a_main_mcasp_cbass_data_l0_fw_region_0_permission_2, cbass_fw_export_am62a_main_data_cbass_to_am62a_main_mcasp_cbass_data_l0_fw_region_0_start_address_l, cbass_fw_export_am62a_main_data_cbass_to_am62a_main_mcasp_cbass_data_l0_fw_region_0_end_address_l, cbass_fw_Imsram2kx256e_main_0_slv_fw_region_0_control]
{0x380C+0x20*i} cbass_fw_export_am62a_main_data_cbass_to_am62a_main_mcasp_cbass_data_l0_fw_region_{i}_permission_2 (i=0..7) — The FW Region {i} Permission 2 Register defines the permissions for the slave export_am62a_main_data_cbass_to_am62a_main_mcasp_cbass_data_l0.slv region {i} firewall.
  fields as cbass_fw_Igpmc_main_0_gpmc_fw_region_0_permission_0
{0x3810+0x20*i} cbass_fw_export_am62a_main_data_cbass_to_am62a_main_mcasp_cbass_data_l0_fw_region_{i}_start_address_l access per field (i=0..7) — The FW Region {i} Start Address Low Register defines the start address bits 31 to 0 for the slave export_am62a_main_data_cbass_to_am62a_main_mcasp_cbass_data_l0.slv region {i} firewall.
  fields as cbass_fw_Igpmc_main_0_gpmc_fw_region_0_start_address_l
{0x3814+0x20*i} cbass_fw_export_am62a_main_data_cbass_to_am62a_main_mcasp_cbass_data_l0_fw_region_{i}_start_address_h (i=0..7) — The FW Region {i} Start Address High Register defines the start address bits 47 to 32 for the slave export_am62a_main_data_cbass_to_am62a_main_mcasp_cbass_data_l0.slv region {i} firewall.
  fields as cbass_fw_Igpmc_main_0_gpmc_fw_region_0_start_address_h
{0x3818+0x20*i} cbass_fw_export_am62a_main_data_cbass_to_am62a_main_mcasp_cbass_data_l0_fw_region_{i}_end_address_l access per field reset 0xFFF (i=0..7) — The FW Region {i} End Address Low Register defines the end address bits 31 to 0 to include for the slave export_am62a_main_data_cbass_to_am62a_main_mcasp_cbass_data_l0.slv region {i} firewall.
  fields as cbass_fw_Igpmc_main_0_gpmc_fw_region_0_end_address_l
{0x381C+0x20*i} cbass_fw_export_am62a_main_data_cbass_to_am62a_main_mcasp_cbass_data_l0_fw_region_{i}_end_address_h (i=0..7) — The FW Region {i} End Address High Register defines the end address bits 47 to 32 to include for the slave export_am62a_main_data_cbass_to_am62a_main_mcasp_cbass_data_l0.slv region {i} firewall.
  fields as cbass_fw_Igpmc_main_0_gpmc_fw_region_0_end_address_h
{0x3C00+0x20*i} cbass_fw_Imsram2kx256e_main_0_slv_fw_region_{i}_control access not given (i=0..15) — The FW Region {i} Control Register defines the control fields for the slave Imsram2kx256e_main_0.slv region {i} firewall.
  fields as cbass_fw_Igpmc_main_0_gpmc_fw_region_0_control
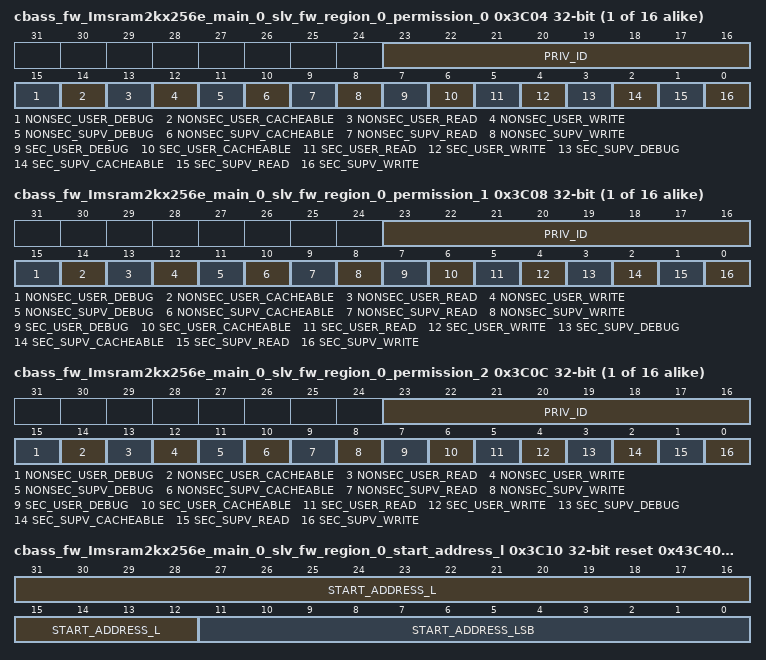
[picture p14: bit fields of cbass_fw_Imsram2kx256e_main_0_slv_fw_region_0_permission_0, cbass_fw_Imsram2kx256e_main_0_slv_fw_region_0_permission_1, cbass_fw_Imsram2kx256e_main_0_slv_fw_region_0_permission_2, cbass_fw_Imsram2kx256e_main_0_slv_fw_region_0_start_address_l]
{0x3C04+0x20*i} cbass_fw_Imsram2kx256e_main_0_slv_fw_region_{i}_permission_0 (i=0..15) — The FW Region {i} Permission 0 Register defines the permissions for the slave Imsram2kx256e_main_0.slv region {i} firewall.
  fields as cbass_fw_Igpmc_main_0_gpmc_fw_region_0_permission_0
{0x3C08+0x20*i} cbass_fw_Imsram2kx256e_main_0_slv_fw_region_{i}_permission_1 (i=0..15) — The FW Region {i} Permission 1 Register defines the permissions for the slave Imsram2kx256e_main_0.slv region {i} firewall.
  fields as cbass_fw_Igpmc_main_0_gpmc_fw_region_0_permission_0
{0x3C0C+0x20*i} cbass_fw_Imsram2kx256e_main_0_slv_fw_region_{i}_permission_2 (i=0..15) — The FW Region {i} Permission 2 Register defines the permissions for the slave Imsram2kx256e_main_0.slv region {i} firewall.
  fields as cbass_fw_Igpmc_main_0_gpmc_fw_region_0_permission_0
0x3C10 cbass_fw_Imsram2kx256e_main_0_slv_fw_region_0_start_address_l access per field reset 0x43C40000 — The FW Region 0 Start Address Low Register defines the start address bits 31 to 0 for the slave Imsram2kx256e_main_0.slv region 0 firewall.
  fields as cbass_fw_Igpmc_main_0_gpmc_fw_region_0_start_address_l
{0x3C14+0x20*i} cbass_fw_Imsram2kx256e_main_0_slv_fw_region_{i}_start_address_h (i=0..15) — The FW Region {i} Start Address High Register defines the start address bits 47 to 32 for the slave Imsram2kx256e_main_0.slv region {i} firewall.
  fields as cbass_fw_Igpmc_main_0_gpmc_fw_region_0_start_address_h
0x3C18 cbass_fw_Imsram2kx256e_main_0_slv_fw_region_0_end_address_l access per field reset 0x43C4FFFF — The FW Region 0 End Address Low Register defines the end address bits 31 to 0 to include for the slave Imsram2kx256e_main_0.slv region 0 firewall.
  fields as cbass_fw_Igpmc_main_0_gpmc_fw_region_0_end_address_l
{0x3C1C+0x20*i} cbass_fw_Imsram2kx256e_main_0_slv_fw_region_{i}_end_address_h (i=0..15) — The FW Region {i} End Address High Register defines the end address bits 47 to 32 to include for the slave Imsram2kx256e_main_0.slv region {i} firewall.
  fields as cbass_fw_Igpmc_main_0_gpmc_fw_region_0_end_address_h
{0x3C10+0x20*i} cbass_fw_Imsram2kx256e_main_0_slv_fw_region_{i}_start_address_l access per field (i=1..15) — The FW Region {i} Start Address Low Register defines the start address bits 31 to 0 for the slave Imsram2kx256e_main_0.slv region {i} firewall.
  fields as cbass_fw_Igpmc_main_0_gpmc_fw_region_0_start_address_l
{0x3C18+0x20*i} cbass_fw_Imsram2kx256e_main_0_slv_fw_region_{i}_end_address_l access per field reset 0xFFF (i=1..15) — The FW Region {i} End Address Low Register defines the end address bits 31 to 0 to include for the slave Imsram2kx256e_main_0.slv region {i} firewall.
  fields as cbass_fw_Igpmc_main_0_gpmc_fw_region_0_end_address_l
